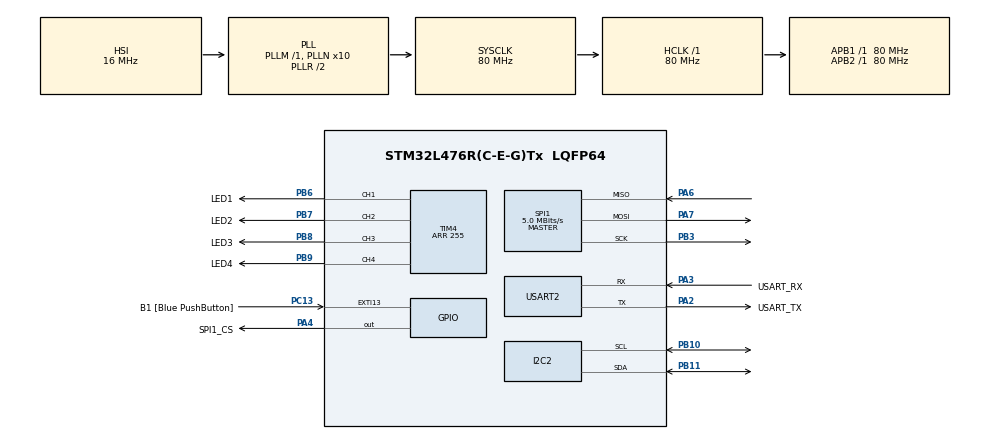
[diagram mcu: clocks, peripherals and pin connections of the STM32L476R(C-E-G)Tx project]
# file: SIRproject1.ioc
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Dma.Request0=SPI1_RX
Dma.Request1=SPI1_TX
Dma.SPI1_RX.0.Direction=DMA_PERIPH_TO_MEMORY
Dma.SPI1_RX.0.Instance=DMA1_Channel2
Dma.SPI1_RX.0.MemDataAlignment=DMA_MDATAALIGN_BYTE
Dma.SPI1_RX.0.MemInc=DMA_MINC_ENABLE
Dma.SPI1_RX.0.Mode=DMA_NORMAL
Dma.SPI1_RX.0.PeriphDataAlignment=DMA_PDATAALIGN_BYTE
Dma.SPI1_RX.0.PeriphInc=DMA_PINC_DISABLE
Dma.SPI1_RX.0.Priority=DMA_PRIORITY_LOW
Dma.SPI1_TX.1.Direction=DMA_MEMORY_TO_PERIPH
Dma.SPI1_TX.1.Instance=DMA1_Channel3
Dma.SPI1_TX.1.MemDataAlignment=DMA_MDATAALIGN_BYTE
Dma.SPI1_TX.1.MemInc=DMA_MINC_ENABLE
Dma.SPI1_TX.1.Mode=DMA_NORMAL
Dma.SPI1_TX.1.PeriphDataAlignment=DMA_PDATAALIGN_BYTE
Dma.SPI1_TX.1.PeriphInc=DMA_PINC_DISABLE
Dma.SPI1_TX.1.Priority=DMA_PRIORITY_LOW
I2C2.Timing=0x10909CEC
Mcu.Family=STM32L4
Mcu.Name=STM32L476R(C-E-G)Tx
Mcu.Package=LQFP64
NVIC.DMA1_Channel2_IRQn=true\:0\:0\:false\:false\:true\:false\:true\:true
NVIC.DMA1_Channel3_IRQn=true\:0\:0\:false\:false\:true\:false\:true\:true
NVIC.I2C2_ER_IRQn=true\:0\:0\:false\:false\:true\:true\:true\:true
NVIC.I2C2_EV_IRQn=true\:0\:0\:false\:false\:true\:true\:true\:true
NVIC.PriorityGroup=NVIC_PRIORITYGROUP_4
NVIC.SPI1_IRQn=true\:0\:0\:false\:false\:true\:true\:true\:true
NVIC.USART2_IRQn=true\:0\:0\:false\:false\:true\:true\:true\:true
PA13\ (JTMS-SWDIO).GPIO_Label=TMS
PA13\ (JTMS-SWDIO).Mode=Serial_Wire
PA13\ (JTMS-SWDIO).Signal=SYS_JTMS-SWDIO
PA14\ (JTCK-SWCLK).GPIO_Label=TCK
PA14\ (JTCK-SWCLK).Mode=Serial_Wire
PA14\ (JTCK-SWCLK).Signal=SYS_JTCK-SWCLK
PA2.GPIO_Label=USART_TX
PA2.GPIO_Mode=GPIO_MODE_AF_PP
PA2.GPIO_PuPd=GPIO_NOPULL
PA2.GPIO_Speed=GPIO_SPEED_FREQ_VERY_HIGH
PA2.Mode=Asynchronous
PA2.Signal=USART2_TX
PA3.GPIO_Label=USART_RX
PA3.GPIO_Mode=GPIO_MODE_AF_PP
PA3.GPIO_PuPd=GPIO_NOPULL
PA3.GPIO_Speed=GPIO_SPEED_FREQ_VERY_HIGH
PA3.Mode=Asynchronous
PA3.Signal=USART2_RX
PA4.GPIO_Label=SPI1_CS
PA4.Signal=GPIO_Output
PA6.Mode=Full_Duplex_Master
PA6.Signal=SPI1_MISO
PA7.Mode=Full_Duplex_Master
PA7.Signal=SPI1_MOSI
PB10.GPIO_Pu=GPIO_NOPULL
PB10.Mode=I2C
PB10.Signal=I2C2_SCL
PB11.GPIO_Pu=GPIO_NOPULL
PB11.Mode=I2C
PB11.Signal=I2C2_SDA
PB3\ (JTDO-TRACESWO).Mode=Full_Duplex_Master
PB3\ (JTDO-TRACESWO).Signal=SPI1_SCK
PB6.GPIO_FM6=__NULL
PB6.GPIO_Label=LED1
PB6.GPIO_ModeDefaultPP=GPIO_MODE_AF_PP
PB6.Signal=S_TIM4_CH1
PB7.GPIO_Label=LED2
PB7.Signal=S_TIM4_CH2
PB8.GPIO_Label=LED3
PB8.Signal=S_TIM4_CH3
PB9.GPIO_Label=LED4
PB9.Signal=S_TIM4_CH4
PC13.GPIO_Label=B1 [Blue PushButton]
PC13.GPIO_ModeDefaultEXTI=GPIO_MODE_IT_FALLING
PC13.GPIO_PuPd=GPIO_NOPULL
PC13.Signal=GPXTI13
PC14-OSC32_IN\ (PC14).Mode=LSE-External-Oscillator
PC14-OSC32_IN\ (PC14).Signal=RCC_OSC32_IN
PC15-OSC32_OUT\ (PC15).Mode=LSE-External-Oscillator
PC15-OSC32_OUT\ (PC15).Signal=RCC_OSC32_OUT
PH0-OSC_IN\ (PH0).Signal=RCC_OSC_IN
PH1-OSC_OUT\ (PH1).Signal=RCC_OSC_OUT
ProjectManager.HeapSize=0x200
ProjectManager.StackSize=0x400
ProjectManager.TargetToolchain=STM32CubeIDE
RCC.ADCFreq_Value=64000000
RCC.AHBFreq_Value=80000000
RCC.APB1Freq_Value=80000000
RCC.APB1TimFreq_Value=80000000
RCC.APB2Freq_Value=80000000
RCC.APB2TimFreq_Value=80000000
RCC.CortexFreq_Value=80000000
RCC.HCLKFreq_Value=80000000
RCC.HSE_VALUE=8000000
RCC.HSI_VALUE=16000000
RCC.MSI_VALUE=4000000
RCC.PLLN=10
RCC.PLLSourceVirtual=RCC_PLLSOURCE_HSI
RCC.PREFETCH_ENABLE=1
RCC.SYSCLKFreq_VALUE=80000000
RCC.SYSCLKSource=RCC_SYSCLKSOURCE_PLLCLK
RCC.USBFreq_Value=64000000
RCC.VCOOutputFreq_Value=160000000
SH.S_TIM4_CH1.0=TIM4_CH1,PWM Generation1 CH1
SH.S_TIM4_CH2.0=TIM4_CH2,PWM Generation2 CH2
SH.S_TIM4_CH3.0=TIM4_CH3,PWM Generation3 CH3
SH.S_TIM4_CH4.0=TIM4_CH4,PWM Generation4 CH4
SPI1.BaudRatePrescaler=SPI_BAUDRATEPRESCALER_16
SPI1.CLKPhase=SPI_PHASE_1EDGE
SPI1.CLKPolarity=SPI_POLARITY_LOW
SPI1.CalculateBaudRate=5.0 MBits/s
SPI1.DataSize=SPI_DATASIZE_8BIT
SPI1.Direction=SPI_DIRECTION_2LINES
SPI1.Mode=SPI_MODE_MASTER
SPI1.VirtualType=VM_MASTER
TIM4.AutoReloadPreload=TIM_AUTORELOAD_PRELOAD_ENABLE
TIM4.Channel-PWM\ Generation1\ CH1=TIM_CHANNEL_1
TIM4.Channel-PWM\ Generation2\ CH2=TIM_CHANNEL_2
TIM4.Channel-PWM\ Generation3\ CH3=TIM_CHANNEL_3
TIM4.Channel-PWM\ Generation4\ CH4=TIM_CHANNEL_4
TIM4.OC1Preload_PWM=ENABLE
TIM4.OCFastMode_PWM-PWM\ Generation1\ CH1=TIM_OCFAST_DISABLE
TIM4.OCFastMode_PWM-PWM\ Generation2\ CH2=TIM_OCFAST_DISABLE
TIM4.OCFastMode_PWM-PWM\ Generation3\ CH3=TIM_OCFAST_DISABLE
TIM4.OCFastMode_PWM-PWM\ Generation4\ CH4=TIM_OCFAST_DISABLE
TIM4.OCPolarity_1=TIM_OCPOLARITY_HIGH
TIM4.OCPolarity_2=TIM_OCPOLARITY_HIGH
TIM4.OCPolarity_3=TIM_OCPOLARITY_HIGH
TIM4.OCPolarity_4=TIM_OCPOLARITY_HIGH
TIM4.Period=255
USART2.VirtualMode-Asynchronous=VM_ASYNC
VP_TIM4_VS_ClockSourceINT.Mode=Internal
board=NUCLEO-L476RG

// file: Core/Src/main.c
/* USER CODE BEGIN Header */
/**
  ******************************************************************************
  * @file           : main.c
  * @brief          : Main program body
  ******************************************************************************
  * @attention
  *
  * Copyright (c) 2024 STMicroelectronics.
  * All rights reserved.
  *
  * This software is licensed under terms that can be found in the LICENSE file
  * in the root directory of this software component.
  * If no LICENSE file comes with this software, it is provided AS-IS.
  *
  ******************************************************************************
  */
/* USER CODE END Header */
#include "main.h"
#include "dma.h"
#include "i2c.h"
#include "spi.h"
#include "tim.h"
#include "usart.h"
#include "gpio.h"

/* USER CODE BEGIN Includes */
#include "stm32l4xx_it.h"
/* USER CODE END Includes */

void SystemClock_Config(void);

int main(void)
{

  /* MCU Configuration--------------------------------------------------------*/

  /* Reset of all peripherals, Initializes the Flash interface and the Systick. */
  HAL_Init();

  /* Configure the system clock */
  SystemClock_Config();

  /* Initialize all configured peripherals */
  MX_GPIO_Init();
  MX_DMA_Init();
  MX_USART2_UART_Init();
  MX_TIM4_Init();
  MX_I2C2_Init();
  MX_SPI1_Init();
  /* USER CODE BEGIN 2 */

  HAL_TIM_Base_Start_IT(&htim4);

  HAL_TIM_PWM_Start(&htim4, TIM_CHANNEL_1);
  HAL_TIM_PWM_Start(&htim4, TIM_CHANNEL_2);
  HAL_TIM_PWM_Start(&htim4, TIM_CHANNEL_3);
  HAL_TIM_PWM_Start(&htim4, TIM_CHANNEL_4);

  __HAL_TIM_SET_COMPARE(&htim4, TIM_CHANNEL_1, 0);
  __HAL_TIM_SET_COMPARE(&htim4, TIM_CHANNEL_2, 0);
  __HAL_TIM_SET_COMPARE(&htim4, TIM_CHANNEL_3, 0);
  __HAL_TIM_SET_COMPARE(&htim4, TIM_CHANNEL_4, 0);

  /* USER CODE END 2 */

  /* Infinite loop */
  /* USER CODE BEGIN WHILE */

  printf("Ready !!! \r\n");
  initized_global = true;

  while (1)
  {

    /* USER CODE END WHILE */

  }
}

void SystemClock_Config(void)
{
  RCC_OscInitTypeDef RCC_OscInitStruct = {0};
  RCC_ClkInitTypeDef RCC_ClkInitStruct = {0};

  /** Configure the main internal regulator output voltage
  */
  if (HAL_PWREx_ControlVoltageScaling(PWR_REGULATOR_VOLTAGE_SCALE1) != HAL_OK)
  {
    Error_Handler();
  }

  /** Initializes the RCC Oscillators according to the specified parameters
  * in the RCC_OscInitTypeDef structure.
  */
  RCC_OscInitStruct.OscillatorType = RCC_OSCILLATORTYPE_HSI;
  RCC_OscInitStruct.HSIState = RCC_HSI_ON;
  RCC_OscInitStruct.HSICalibrationValue = RCC_HSICALIBRATION_DEFAULT;
  RCC_OscInitStruct.PLL.PLLState = RCC_PLL_ON;
  RCC_OscInitStruct.PLL.PLLSource = RCC_PLLSOURCE_HSI;
  RCC_OscInitStruct.PLL.PLLM = 1;
  RCC_OscInitStruct.PLL.PLLN = 10;
  RCC_OscInitStruct.PLL.PLLP = RCC_PLLP_DIV7;
  RCC_OscInitStruct.PLL.PLLQ = RCC_PLLQ_DIV2;
  RCC_OscInitStruct.PLL.PLLR = RCC_PLLR_DIV2;
  if (HAL_RCC_OscConfig(&RCC_OscInitStruct) != HAL_OK)
  {
    Error_Handler();
  }

  /** Initializes the CPU, AHB and APB buses clocks
  */
  RCC_ClkInitStruct.ClockType = RCC_CLOCKTYPE_HCLK|RCC_CLOCKTYPE_SYSCLK
                              |RCC_CLOCKTYPE_PCLK1|RCC_CLOCKTYPE_PCLK2;
  RCC_ClkInitStruct.SYSCLKSource = RCC_SYSCLKSOURCE_PLLCLK;
  RCC_ClkInitStruct.AHBCLKDivider = RCC_SYSCLK_DIV1;
  RCC_ClkInitStruct.APB1CLKDivider = RCC_HCLK_DIV1;
  RCC_ClkInitStruct.APB2CLKDivider = RCC_HCLK_DIV1;

  if (HAL_RCC_ClockConfig(&RCC_ClkInitStruct, FLASH_LATENCY_4) != HAL_OK)
  {
    Error_Handler();
  }
}

void Error_Handler(void)
{
  __disable_irq();
  while (1)
  {
  }
}
